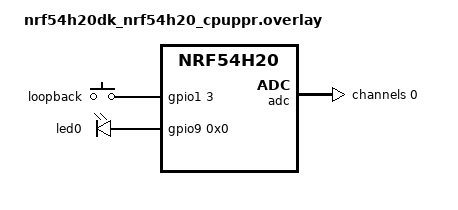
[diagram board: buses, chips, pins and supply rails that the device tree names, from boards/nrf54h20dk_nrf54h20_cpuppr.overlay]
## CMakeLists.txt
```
#
# Copyright (c) 2024 Nordic Semiconductor ASA
#
# SPDX-License-Identifier: LicenseRef-Nordic-5-Clause
#

cmake_minimum_required(VERSION 3.20.0)

find_package(Zephyr REQUIRED HINTS $ENV{ZEPHYR_BASE})
if(NOT SYSBUILD)
  message(FATAL_ERROR
    " This is a multi-image application that should be built using sysbuild.\n"
    " Add --sysbuild argument to west build command to prepare all the images."
  )
endif()

project(idle_adc)

target_sources(app PRIVATE src/main.c)

if(CONFIG_SOC_NRF54H20_CPUPPR)
  message(DEBUG "Power Mode handler for RISC V is included.")
  target_sources(app PRIVATE ${ZEPHYR_NRF_MODULE_DIR}/tests/benchmarks/multicore/common/power_off.c)
endif()
```

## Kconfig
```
#
# Copyright (c) 2025 Nordic Semiconductor ASA
#
# SPDX-License-Identifier: LicenseRef-Nordic-5-Clause
#
config SOC_NRF54H20_CPUPPR
	select HAS_PM
	select HAS_POWEROFF

source "Kconfig.zephyr"
```

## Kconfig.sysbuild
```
#
# Copyright (c) 2024 Nordic Semiconductor ASA
#
# SPDX-License-Identifier: LicenseRef-Nordic-5-Clause
#

choice NETCORE
	default NETCORE_REMOTE_SLEEP_FOREVER

config NETCORE_REMOTE_SLEEP_FOREVER
	bool "Remote sleep forever image"

endchoice

config NETCORE_IMAGE_NAME
	default "remote_sleep_forever" if NETCORE_REMOTE_SLEEP_FOREVER

config NETCORE_IMAGE_PATH
	default "$(ZEPHYR_NRF_MODULE_DIR)/tests/benchmarks/power_consumption/common/remote_sleep_forever" if NETCORE_REMOTE_SLEEP_FOREVER

config SUPPORT_NETCORE
	default y if (SOC_NRF54H20_CPUPPR || SOC_NRF54H20_CPUAPP)

config NETCORE_REMOTE_BOARD_TARGET_CPUCLUSTER
	default "cpurad" if (SOC_NRF54H20_CPUPPR || SOC_NRF54H20_CPUAPP)

if SUPPORT_PPRCORE

choice PPRCORE
	default PPRCORE_REMOTE_SLEEP_FOREVER if SOC_NRF9251_CPUAPP
	default PPRCORE_NONE

config PPRCORE_REMOTE_SLEEP_FOREVER
	bool "Remote sleep forever image"

endchoice

config PPRCORE_IMAGE_NAME
	default "remote_sleep_forever" if PPRCORE_REMOTE_SLEEP_FOREVER

config PPRCORE_IMAGE_PATH
	default "$(ZEPHYR_NRF_MODULE_DIR)/tests/benchmarks/power_consumption/common/remote_sleep_forever" if PPRCORE_REMOTE_SLEEP_FOREVER

endif # SUPPORT_PPRCORE

source "share/sysbuild/Kconfig"
```

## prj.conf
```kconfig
CONFIG_ADC=y
CONFIG_GPIO=y

CONFIG_BOOT_BANNER=n
CONFIG_NCS_BOOT_BANNER=n
CONFIG_ASSERT=y

# Enable for debugging purposes only
CONFIG_PRINTK=n
CONFIG_LOG=n
CONFIG_CONSOLE=n
CONFIG_UART_CONSOLE=n
CONFIG_SERIAL=n
```

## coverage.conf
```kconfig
CONFIG_SOC_NRF54H20_CPURAD_ENABLE=y

CONFIG_ADC=y
CONFIG_GPIO=y

CONFIG_PM=y
CONFIG_PM_DEVICE=y
CONFIG_PM_DEVICE_RUNTIME=y
CONFIG_POWEROFF=y

CONFIG_BOOT_BANNER=n
CONFIG_NCS_BOOT_BANNER=n
CONFIG_ASSERT=n
CONFIG_CLOCK_CONTROL=n

CONFIG_PRINTK=y
CONFIG_LOG=n
CONFIG_CONSOLE=y
CONFIG_UART_CONSOLE=y

CONFIG_LOG_BUFFER_SIZE=16384
```

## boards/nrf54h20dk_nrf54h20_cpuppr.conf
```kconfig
CONFIG_EARLY_CONSOLE=n
```

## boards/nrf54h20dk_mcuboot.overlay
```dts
/*
 * Copyright (c) 2025 Nordic Semiconductor ASA
 *
 * SPDX-License-Identifier: LicenseRef-Nordic-5-Clause
 */

/ {
	aliases {
		/delete-property/ led1;
	};
};

/delete-node/ &led1;
```

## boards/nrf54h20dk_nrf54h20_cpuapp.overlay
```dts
/*
 * Copyright (c) 2025 Nordic Semiconductor ASA
 *
 * SPDX-License-Identifier: LicenseRef-Nordic-5-Clause
 */

/* Required GPIO loopback: P1.02 - P1.03 */
/ {
	aliases {
		adc0 = &adc;
		sw = &loopback;
		led = &led0;
		/delete-property/ led1;
	};

	buttons {
		compatible = "gpio-keys";

		loopback: loopback {
			gpios = <&gpio1 3 GPIO_ACTIVE_HIGH>;
		};
	};
};

/delete-node/ &led1;

&adc {
	#address-cells = <1>;
	#size-cells = <0>;

	channel@0 {
		reg = <0>;
		zephyr,gain = "ADC_GAIN_1";
		zephyr,reference = "ADC_REF_INTERNAL";
		zephyr,acquisition-time = <ADC_ACQ_TIME(ADC_ACQ_TIME_MICROSECONDS, 10)>;
		zephyr,input-positive = <NRF_SAADC_AIN2>;
	};
};

&gpio1 {
	status = "okay";
};
```

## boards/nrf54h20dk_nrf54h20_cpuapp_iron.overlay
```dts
/*
 * Copyright (c) 2025 Nordic Semiconductor ASA
 *
 * SPDX-License-Identifier: LicenseRef-Nordic-5-Clause
 */


/* Required GPIO loopback: P1.02 - P1.03 */
/ {
	aliases {
		adc0 = &adc;
		sw = &loopback;
		led = &led0;
		/delete-property/ led1;
	};
	buttons {
		compatible = "gpio-keys";
		loopback: loopback {
			gpios = <&gpio1 3 GPIO_ACTIVE_HIGH>;
		};
	};
};

/delete-node/ &led1;

&adc {
	#address-cells = <1>;
	#size-cells = <0>;

	channel@0 {
		reg = <0>;
		zephyr,gain = "ADC_GAIN_1";
		zephyr,reference = "ADC_REF_INTERNAL";
		zephyr,acquisition-time = <ADC_ACQ_TIME_DEFAULT>;
		zephyr,input-positive = <NRF_SAADC_AIN2>;
	};

};

&gpio1 {
	status = "okay";
};
```

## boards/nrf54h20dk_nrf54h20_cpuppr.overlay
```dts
/*
 * Copyright (c) 2025 Nordic Semiconductor ASA
 *
 * SPDX-License-Identifier: LicenseRef-Nordic-5-Clause
 */

/* Required GPIO loopback: P1.02 - P1.03 */
/ {
	aliases {
		adc0 = &adc;
		sw = &loopback;
		led = &led0;
	};

	buttons {
		compatible = "gpio-keys";

		loopback: loopback {
			gpios = <&gpio1 3 GPIO_ACTIVE_HIGH>;
		};
	};

	leds {
		compatible = "gpio-leds";

		led0: led_0 {
			gpios = <&gpio9 0x0 0x0>;
		};
	};
};

&adc {
	#address-cells = <1>;
	#size-cells = <0>;
	status = "okay";

	channel@0 {
		reg = <0>;
		zephyr,gain = "ADC_GAIN_1";
		zephyr,reference = "ADC_REF_INTERNAL";
		zephyr,acquisition-time = <ADC_ACQ_TIME_DEFAULT>;
		zephyr,input-positive = <NRF_SAADC_AIN2>;
	};
};

&gpio1 {
	status = "okay";
};

&gpio9 {
	status = "okay";
};

&gpiote130 {
	status = "okay";
};
```

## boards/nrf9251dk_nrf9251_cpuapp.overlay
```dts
/*
 * Copyright (c) 2026 Nordic Semiconductor ASA
 *
 * SPDX-License-Identifier: LicenseRef-Nordic-5-Clause
 */

/* Required GPIO loopback: P1.00 - P1.01 */

/ {
	aliases {
		adc0 = &adc;
		sw = &loopback;
		led = &led0;
	};

	buttons {
		compatible = "gpio-keys";

		loopback: loopback {
			gpios = <&gpio1 1 GPIO_ACTIVE_HIGH>;
		};
	};
};

&adc {
	#address-cells = <1>;
	#size-cells = <0>;

	channel@0 {
		reg = <0>;
		zephyr,gain = "ADC_GAIN_1";
		zephyr,reference = "ADC_REF_INTERNAL";
		zephyr,acquisition-time = <ADC_ACQ_TIME(ADC_ACQ_TIME_MICROSECONDS, 10)>;
		zephyr,input-positive = <NRF_SAADC_AIN0>;
	};
};

&gpio1 {
	status = "okay";
};

&cpuppr_vpr {
	status = "okay";
};

&uart132 {
	status = "reserved";
	interrupt-parent = <&cpuppr_clic>;
};
```

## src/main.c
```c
/*
 * Copyright (c) 2024 Nordic Semiconductor ASA
 *
 * SPDX-License-Identifier: LicenseRef-Nordic-5-Clause
 */

#include <zephyr/kernel.h>
#include <zephyr/drivers/adc.h>
#include <zephyr/drivers/gpio.h>
#define ADC_NODE           DT_ALIAS(adc0)
#define SAMPLES_COUNT      5

/* ADC is configured to have 12 bit resolution (0-4095). */
#define TOLERANCE          40
#define ADC_LOW_LEVEL_MAX  (0 + TOLERANCE)
#define ADC_HIGH_LEVEL_MIN (4095 - TOLERANCE)

static const struct device *adc = DEVICE_DT_GET(ADC_NODE);
static const struct gpio_dt_spec gpio = GPIO_DT_SPEC_GET(DT_ALIAS(sw), gpios);
static const struct gpio_dt_spec led = GPIO_DT_SPEC_GET(DT_ALIAS(led), gpios);

int adc_setup(void)
{
	int ret;
	/* Get the number of channels defined on the DTS. */
	static const struct adc_channel_cfg channel_cfgs[] = {
		DT_FOREACH_CHILD_SEP(ADC_NODE, ADC_CHANNEL_CFG_DT, (,))};

	ret = adc_channel_setup(adc, &channel_cfgs[0]);
	return ret;
}

int main(void)
{
	int err;
	uint16_t channel_reading[SAMPLES_COUNT];
	int test_repetitions = 3;

	err = gpio_is_ready_dt(&led);
	__ASSERT(err, "Error: GPIO Device not ready");

	err = gpio_pin_configure_dt(&led, GPIO_OUTPUT_ACTIVE);
	__ASSERT(err == 0, "Could not configure led GPIO");

	/* Options for the sequence sampling. */
	const struct adc_sequence_options options = {
		.extra_samplings = SAMPLES_COUNT - 1,
		.interval_us = 0,
	};

	struct adc_sequence sequence = {
		.buffer = channel_reading,
		/* buffer size in bytes, not number of samples */
		.buffer_size = sizeof(channel_reading),
		.resolution = 12,
		.options = &options,
		.channels = 1,
	};

	err = gpio_pin_configure_dt(&gpio, GPIO_OUTPUT);
	__ASSERT_NO_MSG(err == 0);
	err = adc_setup();
	__ASSERT_NO_MSG(err == 0);

#if defined(CONFIG_COVERAGE)
	printk("Coverage analysis enabled\n");
	while (test_repetitions--)
#else
	while (test_repetitions)
#endif
	{
		/* Test High input. */
		gpio_pin_set_dt(&led, 1);
		gpio_pin_set_dt(&gpio, 1);
		k_busy_wait(1000);
		err = adc_read(adc, &sequence);
		for (int i = 0; i < SAMPLES_COUNT; i++)	{
			__ASSERT(channel_reading[i] >= ADC_HIGH_LEVEL_MIN,
				"%u: Got unexpected %u", i, channel_reading[i]);
		}
		gpio_pin_set_dt(&led, 0);
		k_sleep(K_SECONDS(1));

		/* Test Low input. */
		gpio_pin_set_dt(&led, 1);
		gpio_pin_set_dt(&gpio, 0);
		k_busy_wait(1000);
		err = adc_read(adc, &sequence);
		for (int i = 0; i < SAMPLES_COUNT; i++)	{
			__ASSERT(channel_reading[i] <= ADC_LOW_LEVEL_MAX,
				"%u: Got unexpected %u", i, channel_reading[i]);
		}
		gpio_pin_set_dt(&led, 0);
		k_sleep(K_SECONDS(1));
	}
#if defined(CONFIG_COVERAGE)
	printk("Coverage analysis start\n");
#endif
	return 0;
}
```
